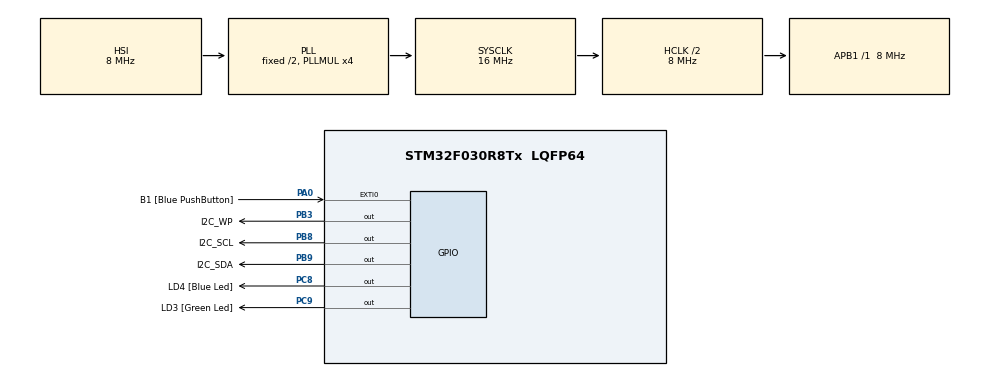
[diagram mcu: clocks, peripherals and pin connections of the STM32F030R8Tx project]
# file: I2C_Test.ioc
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Mcu.Family=STM32F0
Mcu.Name=STM32F030R8Tx
Mcu.Package=LQFP64
PA0.GPIO_Label=B1 [Blue PushButton]
PA0.GPIO_ModeDefaultEXTI=GPIO_MODE_EVT_RISING
PA0.GPIO_PuPd=GPIO_NOPULL
PA0.Signal=GPXTI0
PA13.GPIO_Label=SWDIO
PA13.Mode=Serial-WireDebug
PA13.Signal=SYS_SWDIO
PA14.GPIO_Label=SWCLK
PA14.Mode=Serial-WireDebug
PA14.Signal=SYS_SWCLK
PB3.GPIO_Label=I2C_WP
PB3.GPIO_ModeDefaultOutputPP=GPIO_MODE_OUTPUT_PP
PB3.GPIO_PuPd=GPIO_PULLUP
PB3.GPIO_Speed=GPIO_SPEED_HIGH
PB3.Signal=GPIO_Output
PB8.GPIO_FM8=__NULL
PB8.GPIO_Label=I2C_SCL
PB8.GPIO_ModeDefaultOutputPP=GPIO_MODE_OUTPUT_PP
PB8.GPIO_PuPd=GPIO_PULLUP
PB8.GPIO_Speed=GPIO_SPEED_HIGH
PB8.Signal=GPIO_Output
PB9.GPIO_FM9=__NULL
PB9.GPIO_Label=I2C_SDA
PB9.GPIO_ModeDefaultOutputPP=GPIO_MODE_OUTPUT_PP
PB9.GPIO_PuPd=GPIO_PULLUP
PB9.GPIO_Speed=GPIO_SPEED_HIGH
PB9.Signal=GPIO_Output
PC8.GPIO_Label=LD4 [Blue Led]
PC8.GPIO_ModeDefaultOutputPP=GPIO_MODE_OUTPUT_PP
PC8.GPIO_PuPd=GPIO_NOPULL
PC8.GPIO_Speed=GPIO_SPEED_LOW
PC8.Signal=GPIO_Output
PC9.GPIO_Label=LD3 [Green Led]
PC9.GPIO_ModeDefaultOutputPP=GPIO_MODE_OUTPUT_PP
PC9.GPIO_PuPd=GPIO_NOPULL
PC9.GPIO_Speed=GPIO_SPEED_LOW
PC9.Signal=GPIO_Output
ProjectManager.TargetToolchain=MDK-ARM V5
RCC.AHBCLKDivider=RCC_SYSCLK_DIV2
RCC.AHBFreq_Value=8000000
RCC.APB1Freq_Value=8000000
RCC.APB1TimFreq_Value=8000000
RCC.HCLKFreq_Value=8000000
RCC.PLLMUL=RCC_PLL_MUL4
RCC.SYSCLKFreq_VALUE=16000000
RCC.SYSCLKSource=RCC_SYSCLKSOURCE_PLLCLK
board=STM32F0308-DISCO

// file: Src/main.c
/**
  ******************************************************************************
  * File Name          : main.c
  * Description        : Main program body
  ******************************************************************************
  *
  * COPYRIGHT(c) 2016 STMicroelectronics
  *
  * Redistribution and use in source and binary forms, with or without modification,
  * are permitted provided that the following conditions are met:
  *   1. Redistributions of source code must retain the above copyright notice,
  *      this list of conditions and the following disclaimer.
  *   2. Redistributions in binary form must reproduce the above copyright notice,
  *      this list of conditions and the following disclaimer in the documentation
  *      and/or other materials provided with the distribution.
  *   3. Neither the name of STMicroelectronics nor the names of its contributors
  *      may be used to endorse or promote products derived from this software
  *      without specific prior written permission.
  *
  * THIS SOFTWARE IS PROVIDED BY THE COPYRIGHT HOLDERS AND CONTRIBUTORS "AS IS"
  * AND ANY EXPRESS OR IMPLIED WARRANTIES, INCLUDING, BUT NOT LIMITED TO, THE
  * IMPLIED WARRANTIES OF MERCHANTABILITY AND FITNESS FOR A PARTICULAR PURPOSE ARE
  * DISCLAIMED. IN NO EVENT SHALL THE COPYRIGHT HOLDER OR CONTRIBUTORS BE LIABLE
  * FOR ANY DIRECT, INDIRECT, INCIDENTAL, SPECIAL, EXEMPLARY, OR CONSEQUENTIAL
  * DAMAGES (INCLUDING, BUT NOT LIMITED TO, PROCUREMENT OF SUBSTITUTE GOODS OR
  * SERVICES; LOSS OF USE, DATA, OR PROFITS; OR BUSINESS INTERRUPTION) HOWEVER
  * CAUSED AND ON ANY THEORY OF LIABILITY, WHETHER IN CONTRACT, STRICT LIABILITY,
  * OR TORT (INCLUDING NEGLIGENCE OR OTHERWISE) ARISING IN ANY WAY OUT OF THE USE
  * OF THIS SOFTWARE, EVEN IF ADVISED OF THE POSSIBILITY OF SUCH DAMAGE.
  *
  ******************************************************************************
  */
#include "stm32f0xx_hal.h"
#include "I2C.h"

/* USER CODE BEGIN Includes */
uint32_t var,counter;
/* USER CODE END Inclcounterudes */

/* USER CODE BEGIN PV */
/* Private variables ---------------------------------------------------------*/

/* USER CODE END PV */

void SystemClock_Config(void);
static void MX_GPIO_Init(void);

/* USER CODE BEGIN PFP */
/* Private function prototypes -----------------------------------------------*/

/* USER CODE END PFP */

/* USER CODE BEGIN 0 */

	void delay(uint32_t x){while(x--);}

	uint8_t dat,add;
/* USER CODE END 0 */

int main(void)
{

  /* MCU Configuration----------------------------------------------------------*/

  /* Reset of all peripherals, Initializes the Flash interface and the Systick. */
  HAL_Init();

  /* Configure the system clock */
  SystemClock_Config();

  /* Initialize all configured peripherals */
  MX_GPIO_Init();

  /* Infinite loop */
  while (1)
  {
		counter++;

		Write_iic_byte(dat++,add);

		var  = Read_iic_byte(add++);
		delay(500000);delay(500000);
  }

}

/** System Clock Configuration
*/
void SystemClock_Config(void)
{

  RCC_OscInitTypeDef RCC_OscInitStruct;
  RCC_ClkInitTypeDef RCC_ClkInitStruct;

  RCC_OscInitStruct.OscillatorType = RCC_OSCILLATORTYPE_HSI;
  RCC_OscInitStruct.HSIState = RCC_HSI_ON;
  RCC_OscInitStruct.HSICalibrationValue = 16;
  RCC_OscInitStruct.PLL.PLLState = RCC_PLL_ON;
  RCC_OscInitStruct.PLL.PLLSource = RCC_PLLSOURCE_HSI;
  RCC_OscInitStruct.PLL.PLLMUL = RCC_PLL_MUL4;
  RCC_OscInitStruct.PLL.PREDIV = RCC_PREDIV_DIV1;
  HAL_RCC_OscConfig(&RCC_OscInitStruct);

  RCC_ClkInitStruct.ClockType = RCC_CLOCKTYPE_HCLK|RCC_CLOCKTYPE_SYSCLK;
  RCC_ClkInitStruct.SYSCLKSource = RCC_SYSCLKSOURCE_PLLCLK;
  RCC_ClkInitStruct.AHBCLKDivider = RCC_SYSCLK_DIV2;
  RCC_ClkInitStruct.APB1CLKDivider = RCC_HCLK_DIV1;
  HAL_RCC_ClockConfig(&RCC_ClkInitStruct, FLASH_LATENCY_0);

  HAL_SYSTICK_Config(HAL_RCC_GetHCLKFreq()/1000);

  HAL_SYSTICK_CLKSourceConfig(SYSTICK_CLKSOURCE_HCLK);

}

/** Configure pins as
        * Analog
        * Input
        * Output
        * EVENT_OUT
        * EXTI
*/
void MX_GPIO_Init(void)
{

  GPIO_InitTypeDef GPIO_InitStruct;

  /* GPIO Ports Clock Enable */
  __GPIOA_CLK_ENABLE();
  __GPIOC_CLK_ENABLE();
  __GPIOB_CLK_ENABLE();

  /*Configure GPIO pin : PA0 */
  GPIO_InitStruct.Pin = GPIO_PIN_0;
  GPIO_InitStruct.Mode = GPIO_MODE_EVT_RISING;
  GPIO_InitStruct.Pull = GPIO_NOPULL;
  HAL_GPIO_Init(GPIOA, &GPIO_InitStruct);

  /*Configure GPIO pins : PC8 PC9 */
  GPIO_InitStruct.Pin = GPIO_PIN_8|GPIO_PIN_9;
  GPIO_InitStruct.Mode = GPIO_MODE_OUTPUT_PP;
  GPIO_InitStruct.Pull = GPIO_NOPULL;
  GPIO_InitStruct.Speed = GPIO_SPEED_LOW;
  HAL_GPIO_Init(GPIOC, &GPIO_InitStruct);

  /*Configure GPIO pins : PB3 PB8 PB9 */
  GPIO_InitStruct.Pin = GPIO_PIN_3|GPIO_PIN_8|GPIO_PIN_9;
  GPIO_InitStruct.Mode = GPIO_MODE_OUTPUT_PP;
  GPIO_InitStruct.Pull = GPIO_PULLUP;
  GPIO_InitStruct.Speed = GPIO_SPEED_HIGH;
  HAL_GPIO_Init(GPIOB, &GPIO_InitStruct);

}

/************************ (C) COPYRIGHT STMicroelectronics *****END OF FILE****/
